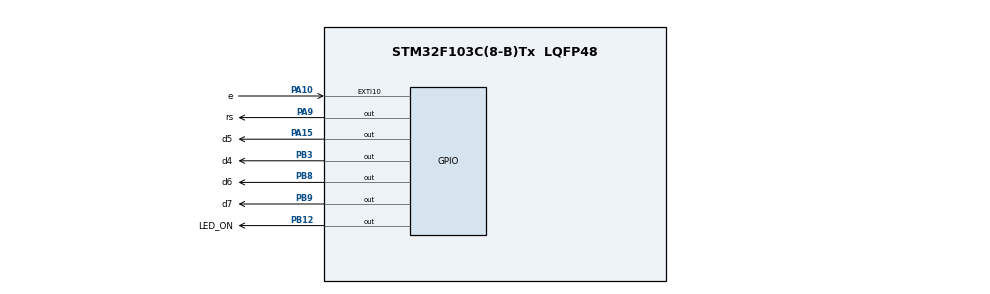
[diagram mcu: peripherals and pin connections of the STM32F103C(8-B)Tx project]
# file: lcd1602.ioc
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Mcu.Family=STM32F1
Mcu.Name=STM32F103C(8-B)Tx
Mcu.Package=LQFP48
NVIC.PriorityGroup=NVIC_PRIORITYGROUP_4
PA10.GPIO_Label=e
PA10.Signal=GPXTI10
PA13.Mode=Serial_Wire
PA13.Signal=SYS_JTMS-SWDIO
PA14.Mode=Serial_Wire
PA14.Signal=SYS_JTCK-SWCLK
PA15.GPIO_Label=d5
PA15.Signal=GPIO_Output
PA9.GPIO_Label=rs
PA9.Signal=GPIO_Output
PB12.GPIO_Label=LED_ON
PB12.Signal=GPIO_Output
PB3.GPIO_Label=d4
PB3.Signal=GPIO_Output
PB8.GPIO_Label=d6
PB8.Signal=GPIO_Output
PB9.GPIO_Label=d7
PB9.Signal=GPIO_Output
PD0-OSC_IN.Mode=HSE-External-Oscillator
PD0-OSC_IN.Signal=RCC_OSC_IN
PD1-OSC_OUT.Mode=HSE-External-Oscillator
PD1-OSC_OUT.Signal=RCC_OSC_OUT
ProjectManager.HeapSize=0x200
ProjectManager.StackSize=0x400
ProjectManager.TargetToolchain=STM32CubeIDE
RCC.APB1Freq_Value=8000000
RCC.APB2Freq_Value=8000000
board=custom

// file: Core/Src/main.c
/* USER CODE BEGIN Header */
/**
  ******************************************************************************
  * @file           : main.c
  * @brief          : Main program body
  ******************************************************************************
  * @attention
  *
  * <h2><center>&copy; Copyright (c) 2020 STMicroelectronics.
  * All rights reserved.</center></h2>
  *
  * This software component is licensed by ST under BSD 3-Clause license,
  * the "License"; You may not use this file except in compliance with the
  * License. You may obtain a copy of the License at:
  *                        opensource.org/licenses/BSD-3-Clause
  *
  ******************************************************************************
  */
/* USER CODE END Header */
#include "main.h"
#include "lcd.h"

/* USER CODE BEGIN PD */
#define INC_LCD_CONFIG_H_
/* USER CODE END PD */

void SystemClock_Config(void);
static void MX_GPIO_Init(void);

int main(void)
{

  /* MCU Configuration--------------------------------------------------------*/

  /* Reset of all peripherals, Initializes the Flash interface and the Systick. */
  HAL_Init();

  /* Configure the system clock */
  SystemClock_Config();

  /* Initialize all configured peripherals */
  MX_GPIO_Init();

  /* Infinite loop */
  /* USER CODE BEGIN WHILE */
  initLCD();
  HAL_GPIO_WritePin(GPIOB, LED_ON_Pin,GPIO_PIN_SET);
  char *stl = "Github";
  writeLCD(stl);
  char *ttl = "LCD Library";
  setCursor(0,1);
  writeLCD(ttl);

  while (1)
  {
    /* USER CODE END WHILE */

  }
}

void SystemClock_Config(void)
{
  RCC_OscInitTypeDef RCC_OscInitStruct = {0};
  RCC_ClkInitTypeDef RCC_ClkInitStruct = {0};

  /** Initializes the RCC Oscillators according to the specified parameters
  * in the RCC_OscInitTypeDef structure.
  */
  RCC_OscInitStruct.OscillatorType = RCC_OSCILLATORTYPE_HSI;
  RCC_OscInitStruct.HSIState = RCC_HSI_ON;
  RCC_OscInitStruct.HSICalibrationValue = RCC_HSICALIBRATION_DEFAULT;
  RCC_OscInitStruct.PLL.PLLState = RCC_PLL_NONE;
  if (HAL_RCC_OscConfig(&RCC_OscInitStruct) != HAL_OK)
  {
    Error_Handler();
  }

  /** Initializes the CPU, AHB and APB buses clocks
  */
  RCC_ClkInitStruct.ClockType = RCC_CLOCKTYPE_HCLK|RCC_CLOCKTYPE_SYSCLK
                              |RCC_CLOCKTYPE_PCLK1|RCC_CLOCKTYPE_PCLK2;
  RCC_ClkInitStruct.SYSCLKSource = RCC_SYSCLKSOURCE_HSI;
  RCC_ClkInitStruct.AHBCLKDivider = RCC_SYSCLK_DIV1;
  RCC_ClkInitStruct.APB1CLKDivider = RCC_HCLK_DIV1;
  RCC_ClkInitStruct.APB2CLKDivider = RCC_HCLK_DIV1;

  if (HAL_RCC_ClockConfig(&RCC_ClkInitStruct, FLASH_LATENCY_0) != HAL_OK)
  {
    Error_Handler();
  }
}

static void MX_GPIO_Init(void)
{
  GPIO_InitTypeDef GPIO_InitStruct = {0};

  /* GPIO Ports Clock Enable */
  __HAL_RCC_GPIOD_CLK_ENABLE();
  __HAL_RCC_GPIOB_CLK_ENABLE();
  __HAL_RCC_GPIOA_CLK_ENABLE();

  /*Configure GPIO pin Output Level */
  HAL_GPIO_WritePin(GPIOB, LED_ON_Pin|d4_Pin|d6_Pin|d7_Pin, GPIO_PIN_RESET);

  /*Configure GPIO pin Output Level */
  HAL_GPIO_WritePin(GPIOA, rs_Pin|d5_Pin, GPIO_PIN_RESET);

  /*Configure GPIO pins : LED_ON_Pin d4_Pin d6_Pin d7_Pin */
  GPIO_InitStruct.Pin = LED_ON_Pin|d4_Pin|d6_Pin|d7_Pin;
  GPIO_InitStruct.Mode = GPIO_MODE_OUTPUT_PP;
  GPIO_InitStruct.Pull = GPIO_NOPULL;
  GPIO_InitStruct.Speed = GPIO_SPEED_FREQ_LOW;
  HAL_GPIO_Init(GPIOB, &GPIO_InitStruct);

  /*Configure GPIO pins : rs_Pin d5_Pin */
  GPIO_InitStruct.Pin = rs_Pin|d5_Pin;
  GPIO_InitStruct.Mode = GPIO_MODE_OUTPUT_PP;
  GPIO_InitStruct.Pull = GPIO_NOPULL;
  GPIO_InitStruct.Speed = GPIO_SPEED_FREQ_LOW;
  HAL_GPIO_Init(GPIOA, &GPIO_InitStruct);

  /*Configure GPIO pin : e_Pin */
  GPIO_InitStruct.Pin = e_Pin;
  GPIO_InitStruct.Mode = GPIO_MODE_IT_RISING;
  GPIO_InitStruct.Pull = GPIO_NOPULL;
  HAL_GPIO_Init(e_GPIO_Port, &GPIO_InitStruct);

}

void Error_Handler(void)
{
  __disable_irq();
  while (1)
  {
  }
}
